AUTOSAR XML (schema 4-0-3)
package /ComponentTypes
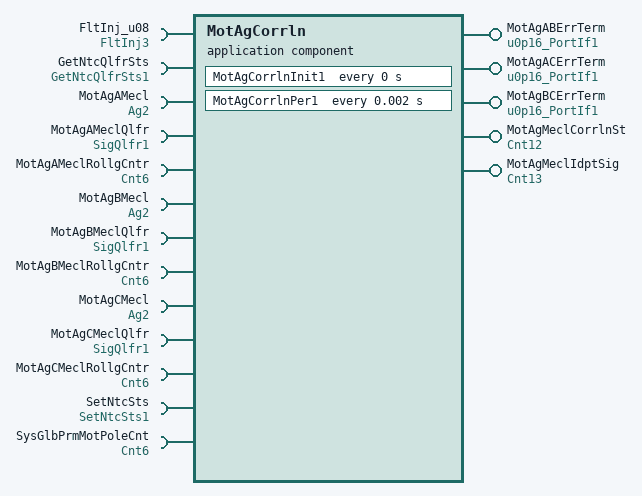
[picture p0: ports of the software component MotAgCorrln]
  application sw component type MotAgCorrln
    5 x provide port:
      MotAgABErrTerm: nonqueued-sender-com-spec{data-element=Val, init-value=0}, provided-interface=u0p16_PortIf1
      MotAgACErrTerm: nonqueued-sender-com-spec{data-element=Val, init-value=0}, provided-interface=u0p16_PortIf1
      MotAgBCErrTerm: nonqueued-sender-com-spec{data-element=Val, init-value=0}, provided-interface=u0p16_PortIf1
      MotAgMeclCorrlnSt: nonqueued-sender-com-spec{data-element=Val, init-value=7}, provided-interface=Cnt12
      MotAgMeclIdptSig: nonqueued-sender-com-spec{data-element=Val, init-value=3}, provided-interface=Cnt13
    13 x require port:
      FltInj_u08: client-com-spec=Oper, required-interface=FltInj3
      GetNtcQlfrSts: client-com-spec=Oper, required-interface=GetNtcQlfrSts1
      MotAgAMecl: nonqueued-receiver-com-spec{data-element=Val, filter=data-filter-type=ALWAYS, init-value=0}, required-interface=Ag2
      MotAgAMeclQlfr: nonqueued-receiver-com-spec{data-element=Val, filter=data-filter-type=ALWAYS, init-value=0}, required-interface=SigQlfr1
      MotAgAMeclRollgCntr: nonqueued-receiver-com-spec{data-element=Val, filter=data-filter-type=ALWAYS, init-value=0}, required-interface=Cnt6
      MotAgBMecl: nonqueued-receiver-com-spec{data-element=Val, filter=data-filter-type=ALWAYS, init-value=0}, required-interface=Ag2
      MotAgBMeclQlfr: nonqueued-receiver-com-spec{data-element=Val, filter=data-filter-type=ALWAYS, init-value=0}, required-interface=SigQlfr1
      MotAgBMeclRollgCntr: nonqueued-receiver-com-spec{data-element=Val, filter=data-filter-type=ALWAYS, init-value=0}, required-interface=Cnt6
      MotAgCMecl: nonqueued-receiver-com-spec{data-element=Val, filter=data-filter-type=ALWAYS, init-value=0}, required-interface=Ag2
      MotAgCMeclQlfr: nonqueued-receiver-com-spec{data-element=Val, filter=data-filter-type=ALWAYS, init-value=0}, required-interface=SigQlfr1
      MotAgCMeclRollgCntr: nonqueued-receiver-com-spec{data-element=Val, filter=data-filter-type=ALWAYS, init-value=0}, required-interface=Cnt6
      SetNtcSts: client-com-spec=Oper, required-interface=SetNtcSts1
      SysGlbPrmMotPoleCnt: parameter-require-com-spec{init-value=6, parameter=Val}, required-interface=Cnt6
    behavior MotAgCorrln_InternalBehavior: data-type-mapping=Nexteer
      ar-typed-per-instance-memorys:
        10 x data, all with sw-calibration-access=READ-ONLY:
          dMotAgCorrlnMotAgAOk: type=boolean
          dMotAgCorrlnMotAgBOk: type=boolean
          dMotAgCorrlnMotAgCOk: type=boolean
          MotAgCorrlnErrThd: type=u0p16
          MotAgCorrlnMotAgARollgCntPrev: type=uint8
          MotAgCorrlnMotAgAStallCntPrev: type=uint8
          MotAgCorrlnMotAgBRollgCntPrev: type=uint8
          MotAgCorrlnMotAgBStallCntPrev: type=uint8
          MotAgCorrlnMotAgCRollgCntPrev: type=uint8
          MotAgCorrlnMotAgCStallCntPrev: type=uint8
      timing event MotAgCorrln_InitEvent: start-on-event=MotAgCorrlnInit1, period=0
      timing event TMT_MotAgCorrlnPer1: start-on-event=MotAgCorrlnPer1, period=0.002
      runnable MotAgCorrlnInit1
      runnable MotAgCorrlnPer1
        data-receive-point-by-arguments:
          9 x access:
            REC_MotAgAMecl_Val_1: accessed-variable=MotAgAMecl.Val
            REC_MotAgAMeclQlfr_Val: accessed-variable=MotAgAMeclQlfr.Val
            REC_MotAgAMeclRollgCntr_Val: accessed-variable=MotAgAMeclRollgCntr.Val
            REC_MotAgBMecl_Val_1: accessed-variable=MotAgBMecl.Val
            REC_MotAgBMeclQlfr_Val: accessed-variable=MotAgBMeclQlfr.Val
            REC_MotAgBMeclRollgCntr_Val: accessed-variable=MotAgBMeclRollgCntr.Val
            REC_MotAgCMecl_Val_1: accessed-variable=MotAgCMecl.Val
            REC_MotAgCMeclQlfr_Val: accessed-variable=MotAgCMeclQlfr.Val
            REC_MotAgCMeclRollgCntr_Val: accessed-variable=MotAgCMeclRollgCntr.Val
        data-send-points:
          5 x access:
            SEND_MotAgABErrTerm_Val: accessed-variable=MotAgABErrTerm.Val
            SEND_MotAgACErrTerm_Val: accessed-variable=MotAgACErrTerm.Val
            SEND_MotAgBCErrTerm_Val: accessed-variable=MotAgBCErrTerm.Val
            SEND_MotAgMeclCorrlnSt_Val_1: accessed-variable=MotAgMeclCorrlnSt.Val
            SEND_MotAgMeclIdptSig_Val: accessed-variable=MotAgMeclIdptSig.Val
        sync call SC_FltInj_u08_Oper: operation=FltInj_u08.Oper, timeout=0
        sync call SC_GetNtcQlfrSts1_Oper: operation=GetNtcQlfrSts.Oper, timeout=0
        sync call SC_SetNtcSts_Oper: operation=SetNtcSts.Oper, timeout=0
  swc implementation MotAgCorrln_Implementation: behavior=MotAgCorrln_InternalBehavior
    code-descriptors:
      code Default: artifact-descriptors=autosar-engineering-object={short-label=Default, category=SWSRC}
